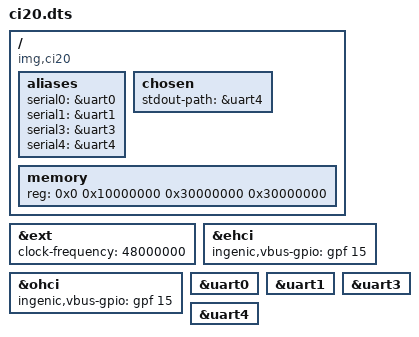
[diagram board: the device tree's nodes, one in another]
/dts-v1/;

#include <dt-bindings/gpio/gpio.h>
#include "jz4780.dtsi"

/ {
	compatible = "img,ci20", "ingenic,jz4780";

	aliases {
		serial0 = &uart0;
		serial1 = &uart1;
		serial3 = &uart3;
		serial4 = &uart4;
	};

	chosen {
		stdout-path = &uart4;
	};

	memory {
		device_type = "memory";
		reg = <0x0 0x10000000
		       0x30000000 0x30000000>;
	};
};

&ext {
	clock-frequency = <48000000>;
};

&ehci {
    ingenic,vbus-gpio = <&gpf 15 0>;
};

&ohci {
    ingenic,vbus-gpio = <&gpf 15 0>;
};

&uart0 {
	status = "okay";
};

&uart1 {
	status = "okay";
};

&uart3 {
	status = "okay";
};

&uart4 {
	status = "okay";
};
